# MAILBOX_L4_CFGInterconnect register map
Vendor: Texas Instruments
Peripheral module from a debugger description file (folder omap5430_ES2_PUBLIC).
Registers are 32-bit, read-write, reset 0x0 unless marked. A register's access mark holds for its fields unless they carry their own. Offsets are as the file gives them; lines under a group give offsets from that group; [hi:lo] are bit positions; {n}, {i} and the like mark numbered series; 'fields as' and 'values as' point back to an identical list; <NAME> marks a mode.

## MAILBOX_L4_CFGInterconnect
0x00 MAILBOX_REVISION ro reset not defined — This register contains the IP revision code
  [31:0] REVISION — IP Revision
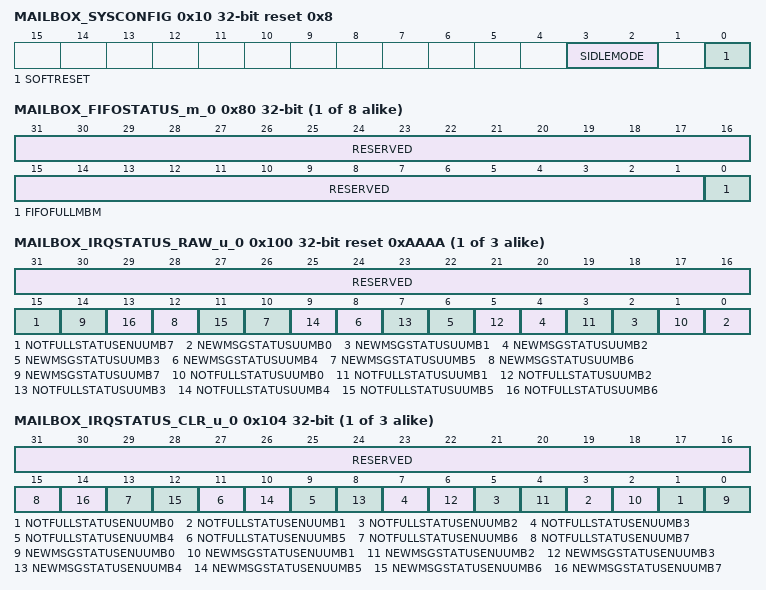
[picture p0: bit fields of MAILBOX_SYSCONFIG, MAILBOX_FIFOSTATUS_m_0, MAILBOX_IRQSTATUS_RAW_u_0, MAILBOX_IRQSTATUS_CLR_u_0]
0x10 MAILBOX_SYSCONFIG reset 0x8 — This register controls the various parameters of the communication interface
  [3:2] SIDLEMODE — Idle Mode
    0=b00 (Force-idle. An idle request is acknowledged unconditionally); 1=b01 (No-idle. An idle request is never acknowledged); 2=b10 (Smart-idle. Acknowledgement to an idle request is given based on the internal activity of the module based on the internal activity of the module); 3=b11 (reserved do not use)
  [0] SOFTRESET
    0=b0 (Soft/Hard reset done); 0=b0 (No action); 1=b1 (Reset is ongoing); 1=b1 (Start the soft reset sequence)
{0x40+4i} MAILBOX_MESSAGE_m_{i} (i=0..7) — The message register stores the next to be read message of the mailbox. Reads remove the message from the FIFO queue.
  [31:0] MESSAGEVALUEMBM — Message in Mailbox
{0x80+4i} MAILBOX_FIFOSTATUS_m_{i} ro (i=0..7) — The FIFO status register has the status related to the mailbox internal FIFO
  [31:1] RESERVED — Reads returns 0
  [0] FIFOFULLMBM — Full flag for Mailbox
    0=Mailbox_FIFO_is_not_full; 1=Mailbox_FIFO_is_full
{0xC0+4i} MAILBOX_MSGSTATUS_m_{i} ro (i=0..7) — The message status register has the status of the messages in the mailbox.
  [2:0] NBOFMSGMBM — Number of unread messages in Mailbox Note: Limited to four messages per mailbox.
{0x100+0x10*i} MAILBOX_IRQSTATUS_RAW_u_{i} reset 0xAAAA (i=0..2) — The interrupt status register has the raw status for each event that may be responsible for the generation of an interrupt to the corresponding user - write 1 to a given bit sets this bit. This register is mainly used for debug purpose.
  [31:16] RESERVED — Write 0's for future compatibility. Read returns 0.
  [15] NOTFULLSTATUSENUUMB7 — NotFull Status bit for User u, Mailbox 7
    0=No_event_pending_(message_queue_full); 0=No_action; 1=Event_pending_(message_queue_not_full); 1=Set_the_event_(for_debug)
  [2n] NEWMSGSTATUSUUMB{n} (n=0..7) — NewMessage Status bit for User u, Mailbox {n}
    0=No_event_(message)_pending; 0=No_action; 1=Event_(message)_pending; 1=Set_the_event_(for_debug)
  [2n+1] NOTFULLSTATUSUUMB{n} (n=0..6) — NotFull Status bit for User u, Mailbox {n}
    values as NOTFULLSTATUSENUUMB7
{0x104+0x10*i} MAILBOX_IRQSTATUS_CLR_u_{i} (i=0..2) — The interrupt status register has the status combined with irq-enable for each event that may be responsible for the generation of an interrupt to the corresponding user - write 1 to a given bit resets this bit
  [31:16] RESERVED — Write 0's for future compatibility. Read returns 0.
  [2n+1] NOTFULLSTATUSENUUMB{n} (n=0..7) — NotFull Status bit for User u, Mailbox {n}
    0=No_event_pending_(message_queue_full); 0=No_action; 1=Event_pending_(message_queue_not_full); 1=Clear_pending_event,_if_any
  [2n] NEWMSGSTATUSENUUMB{n} (n=0..7) — NewMessage Status bit for User u, Mailbox {n}
    0=No_event_(message)_pending; 0=No_action; 1=Event_(message)_pending; 1=Clear_pending_event,_if_any
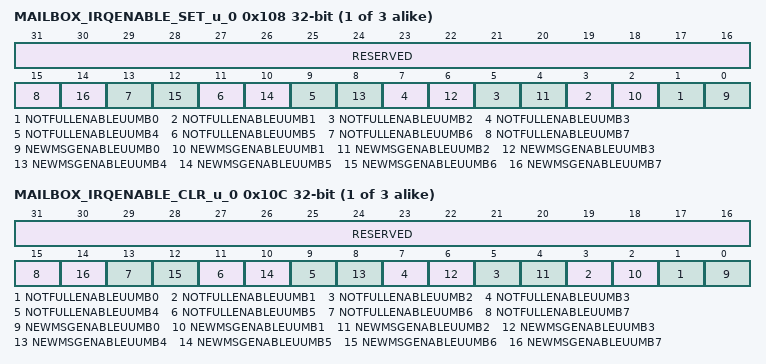
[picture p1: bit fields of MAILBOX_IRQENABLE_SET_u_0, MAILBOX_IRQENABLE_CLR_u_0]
{0x108+0x10*i} MAILBOX_IRQENABLE_SET_u_{i} (i=0..2) — The interrupt enable register enables to unmask the module internal source of interrupt to the corresponding user. This register is write 1 to set.
  [31:16] RESERVED — Write 0's for future compatibility. Read returns 0.
  [2n+1] NOTFULLENABLEUUMB{n} (n=0..7) — NotFull Enable bit for User u, Mailbox {n}
    0=Interupt_disabled; 0=No_action; 1=Interrupt_enabled; 1=Enable_interrupt
  [2n] NEWMSGENABLEUUMB{n} (n=0..7) — NewMessage Enable bit for User u, Mailbox {n}
    values as NOTFULLENABLEUUMB0
{0x10C+0x10*i} MAILBOX_IRQENABLE_CLR_u_{i} (i=0..2) — The interrupt enable register enables to mask the module internal source of interrupt to the corresponding user. This register is write 1 to clear.
  [31:16] RESERVED — Write 0's for future compatibility. Read returns 0.
  [2n+1] NOTFULLENABLEUUMB{n} (n=0..7) — NotFull Enable bit for User u, Mailbox {n}
    0=Interupt_disabled; 0=No_action; 1=Interrupt_enabled; 1=Disable_interrupt
  [2n] NEWMSGENABLEUUMB{n} (n=0..7) — NewMessage Enable bit for User u, Mailbox {n}
    values as NOTFULLENABLEUUMB0
